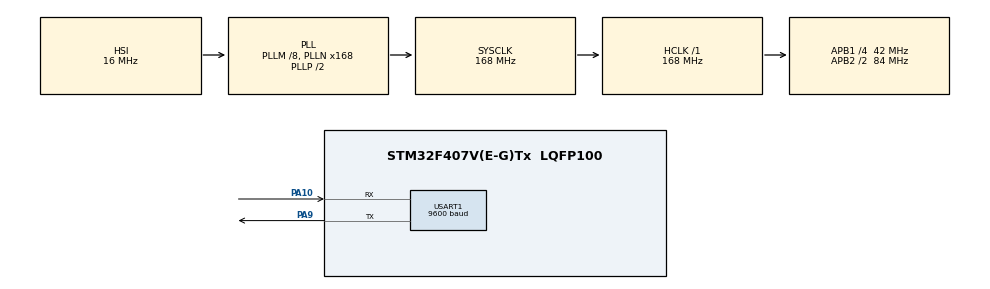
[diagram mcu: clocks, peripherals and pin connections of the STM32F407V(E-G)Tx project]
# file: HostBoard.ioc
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Mcu.Family=STM32F4
Mcu.Name=STM32F407V(E-G)Tx
Mcu.Package=LQFP100
NVIC.PriorityGroup=NVIC_PRIORITYGROUP_4
NVIC.USART1_IRQn=true\:5\:0\:true\:false\:true\:true\:true\:true
PA10.Mode=Asynchronous
PA10.Signal=USART1_RX
PA9.Mode=Asynchronous
PA9.Signal=USART1_TX
ProjectManager.HeapSize=0x200
ProjectManager.StackSize=0x400
ProjectManager.TargetToolchain=CMake
RCC.48MHZClocksFreq_Value=84000000
RCC.AHBFreq_Value=168000000
RCC.APB1CLKDivider=RCC_HCLK_DIV4
RCC.APB1Freq_Value=42000000
RCC.APB1TimFreq_Value=84000000
RCC.APB2CLKDivider=RCC_HCLK_DIV2
RCC.APB2Freq_Value=84000000
RCC.APB2TimFreq_Value=168000000
RCC.CortexFreq_Value=168000000
RCC.HCLKFreq_Value=168000000
RCC.HSE_VALUE=25000000
RCC.HSI_VALUE=16000000
RCC.LSE_VALUE=32768
RCC.PLLM=8
RCC.PLLN=168
RCC.SYSCLKFreq_VALUE=168000000
RCC.SYSCLKSource=RCC_SYSCLKSOURCE_PLLCLK
RCC.VCOOutputFreq_Value=336000000
USART1.BaudRate=9600
USART1.VirtualMode=VM_ASYNC
board=custom

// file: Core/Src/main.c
/* USER CODE BEGIN Header */
/**
  ******************************************************************************
  * @file           : main.c
  * @brief          : Main program body
  ******************************************************************************
  * @attention
  *
  * Copyright (c) 2026 STMicroelectronics.
  * All rights reserved.
  *
  * This software is licensed under terms that can be found in the LICENSE file
  * in the root directory of this software component.
  * If no LICENSE file comes with this software, it is provided AS-IS.
  *
  ******************************************************************************
  */
/* USER CODE END Header */
#include "main.h"
#include "usart.h"
#include "gpio.h"

/* USER CODE BEGIN Includes */
#include "FreeRTOS.h"
#include "modbus_host.h"
#include "modbus_rtu.h"
#include "task.h"

/* USER CODE END Includes */

void SystemClock_Config(void);
/* USER CODE BEGIN PFP */
static void ModbusHostTask(void *argument);

/* USER CODE END PFP */

/* USER CODE BEGIN 0 */

static void ModbusHostTask(void *argument)
{
  uint8_t request[MODBUS_HOST_MAX_ADU_SIZE];
  uint8_t response[MODBUS_HOST_MAX_ADU_SIZE];
  uint16_t requestLen;
  uint16_t writeValues[2] = {0x0001U, 0x0002U};
  ModbusHost_ResponseInfo_t info;

  (void)argument;

  for (;;)
  {
    requestLen = ModbusHost_BuildReadHoldingReq(MODBUS_HOST_DEFAULT_SLAVE_ADDR, 0U, 2U, request, sizeof(request));
    (void)ModbusHost_SendRequest(request, requestLen, response, sizeof(response), &info);

    requestLen = ModbusHost_BuildWriteMultipleRegsReq(MODBUS_HOST_DEFAULT_SLAVE_ADDR, 0U, 2U, writeValues, request, sizeof(request));
    (void)ModbusHost_SendRequest(request, requestLen, response, sizeof(response), &info);

    vTaskDelay(pdMS_TO_TICKS(1000U));
  }
}

/* USER CODE END 0 */

int main(void)
{

  /* MCU Configuration--------------------------------------------------------*/

  /* Reset of all peripherals, Initializes the Flash interface and the Systick. */
  HAL_Init();

  /* Configure the system clock */
  SystemClock_Config();

  /* Initialize all configured peripherals */
  MX_GPIO_Init();
  MX_USART1_UART_Init();
  /* USER CODE BEGIN 2 */
  if (ModbusHost_Init() == 0U)
  {
    Error_Handler();
  }
  ModbusRtu_Init(&huart1);
  (void)xTaskCreate(ModbusHostTask, "mb_host", 384U, NULL, tskIDLE_PRIORITY + 1U, NULL);
  vTaskStartScheduler();

  /* USER CODE END 2 */

  /* Infinite loop */
  while (1)
  {

  }
}

void SystemClock_Config(void)
{
  RCC_OscInitTypeDef RCC_OscInitStruct = {0};
  RCC_ClkInitTypeDef RCC_ClkInitStruct = {0};

  /** Configure the main internal regulator output voltage
  */
  __HAL_RCC_PWR_CLK_ENABLE();
  __HAL_PWR_VOLTAGESCALING_CONFIG(PWR_REGULATOR_VOLTAGE_SCALE1);

  /** Initializes the RCC Oscillators according to the specified parameters
  * in the RCC_OscInitTypeDef structure.
  */
  RCC_OscInitStruct.OscillatorType = RCC_OSCILLATORTYPE_HSI;
  RCC_OscInitStruct.HSIState = RCC_HSI_ON;
  RCC_OscInitStruct.HSICalibrationValue = RCC_HSICALIBRATION_DEFAULT;
  RCC_OscInitStruct.PLL.PLLState = RCC_PLL_ON;
  RCC_OscInitStruct.PLL.PLLSource = RCC_PLLSOURCE_HSI;
  RCC_OscInitStruct.PLL.PLLM = 8;
  RCC_OscInitStruct.PLL.PLLN = 168;
  RCC_OscInitStruct.PLL.PLLP = RCC_PLLP_DIV2;
  RCC_OscInitStruct.PLL.PLLQ = 4;
  if (HAL_RCC_OscConfig(&RCC_OscInitStruct) != HAL_OK)
  {
    Error_Handler();
  }

  /** Initializes the CPU, AHB and APB buses clocks
  */
  RCC_ClkInitStruct.ClockType = RCC_CLOCKTYPE_HCLK|RCC_CLOCKTYPE_SYSCLK
                              |RCC_CLOCKTYPE_PCLK1|RCC_CLOCKTYPE_PCLK2;
  RCC_ClkInitStruct.SYSCLKSource = RCC_SYSCLKSOURCE_PLLCLK;
  RCC_ClkInitStruct.AHBCLKDivider = RCC_SYSCLK_DIV1;
  RCC_ClkInitStruct.APB1CLKDivider = RCC_HCLK_DIV4;
  RCC_ClkInitStruct.APB2CLKDivider = RCC_HCLK_DIV2;

  if (HAL_RCC_ClockConfig(&RCC_ClkInitStruct, FLASH_LATENCY_5) != HAL_OK)
  {
    Error_Handler();
  }
}

/* USER CODE BEGIN 4 */

void vApplicationStackOverflowHook(TaskHandle_t xTask, char *pcTaskName)
{
  (void)xTask;
  (void)pcTaskName;
  __disable_irq();
  while (1)
  {
  }
}

/* USER CODE END 4 */

void Error_Handler(void)
{
  __disable_irq();
  while (1)
  {
  }
}
